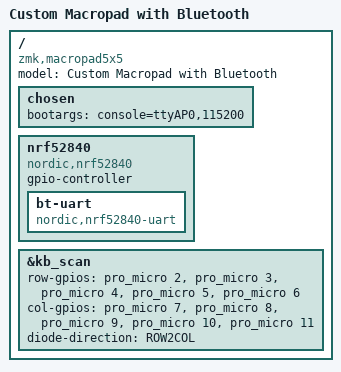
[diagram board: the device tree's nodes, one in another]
/dts-v1/;
/ {
    model = "Custom Macropad with Bluetooth";
    compatible = "zmk,macropad5x5";

    chosen {
        bootargs = "console=ttyAP0,115200";
    };

    nrf52840 {
        compatible = "nordic,nrf52840";
        gpio-controller;
        #gpio-cells = <2>;

        bt-uart {
            compatible = "nordic,nrf52840-uart";
            status = "okay";
        };
    };

    &kb_scan {
        row-gpios = <&pro_micro 2 0>, <&pro_micro 3 0>, <&pro_micro 4 0>, <&pro_micro 5 0>, <&pro_micro 6 0>;
        col-gpios = <&pro_micro 7 0>, <&pro_micro 8 0>, <&pro_micro 9 0>, <&pro_micro 10 0>, <&pro_micro 11 0>;
        diode-direction = "ROW2COL";
    };
};
